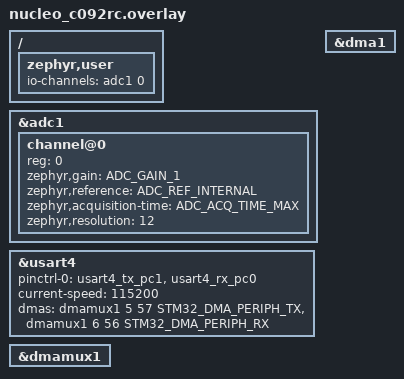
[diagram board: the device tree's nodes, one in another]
/*
 * SPDX-License-Identifier: Apache-2.0
 *
 * Copyright (c) 2025 STMicroelectronics
 * Copyright (c) 2025 Thomas Stranger
 */

/ {
	zephyr,user {
		/* adjust channel number according to pinmux in board.dts */
		io-channels = <&adc1 0>;
	};
};

&adc1 {
	#address-cells = <1>;
	#size-cells = <0>;

	channel@0 {
		reg = <0>;
		zephyr,gain = "ADC_GAIN_1";
		zephyr,reference = "ADC_REF_INTERNAL";
		zephyr,acquisition-time = <ADC_ACQ_TIME_MAX>;
		zephyr,resolution = <12>;
	};
};

&usart4 {
	pinctrl-0 = <&usart4_tx_pc1 &usart4_rx_pc0>;
	pinctrl-names = "default";
	current-speed = <115200>;
	status = "okay";
};

dut: &usart4 {
	dmas = <&dmamux1 5 57 STM32_DMA_PERIPH_TX>,
	       <&dmamux1 6 56 STM32_DMA_PERIPH_RX>;
	dma-names = "tx", "rx";
};

&dma1 {
	status = "okay";
};

&dmamux1 {
	status = "okay";
};
